# A31G324 register map
Vendor: ABOV Semiconductor Co., Ltd.; Series: A31G324; File version: 1.0
CPU: CM0PLUS r0p1, little endian, no MPU, no FPU, VTOR, 2 interrupt priority bits
Registers are 32-bit, read-write, reset 0x0 unless marked. A register's access mark holds for its fields unless they carry their own. Offsets are from the block's base; [hi:lo] are bit positions.

## DAC — 12-BIT D/A CONVERTER
Base 0x40003500
0x00 DR — D/A Converter Data Register
  [15:0] DACDR — D/A Converter Data (16-bit) The DACDR[15:0] is a binary format.
0x04 BR ro — D/A Converter Buffer Register
  [15:0] DACBR — D/A Converter Buffer Data (16-bit) The DACBR[15:0] is a binary format.
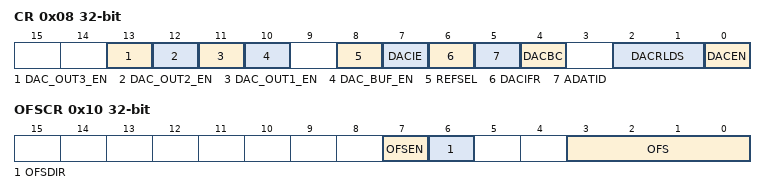
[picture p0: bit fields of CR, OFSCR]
0x08 CR — D/A Converter Control Register
  [13] DAC_OUT3_EN — DAC_OUT3 output enable 0:Disable, 1: Enable
  [12] DAC_OUT2_EN — DAC_OUT2 output enable 0:Disable, 1: Enable
  [11] DAC_OUT1_EN — DAC_OUT1 output enable 0:Disable, 1: Enable
  [10] DAC_BUF_EN — DAC Reference Selection 0:Disable, 1: Enable
  [8] REFSEL — DAC Reference Selection 0:AVDD, 1: DAVREF Pin
  [7] DACIE — Enable or Disable D/AC Interrupt
  [6] DACIFR — When D/AC Interrupt occurs, this bit becomes '1'. The flag is cleared only by writing a '0' to the bit. So, the flag should be cleared by software. This interrupt is for a result that the DACDRH register automatically increments to "800xH" or decrements to "000xH". Write '1' has no effect.
  [5] ADATID — Automatically D/A Converter Data Increment/Decrement
  [4] DACBC — D/A Converter Buffer Clear
  [2:1] DACRLDS — D/A Converter Reload Selection. These bits select a reload signal to load data from D/AC data register to buffer.
  [0] DACEN — D/A Converter Enable Bit
0x0C PGSR reset 0x5 — Programmable Gain Control Register
  [3:0] DACPGSR — Programmable Gain Selection
0x10 OFSCR — D/A Converter Offset Control Register
  [7] OFSEN — D/AC Offset Control Enable Bit
  [6] OFSDIR — D/AC Offset Direction Selection Bit
  [3:0] OFS — D/AC Offset Value

## COMP — COMPARATOR
Base 0x40003420
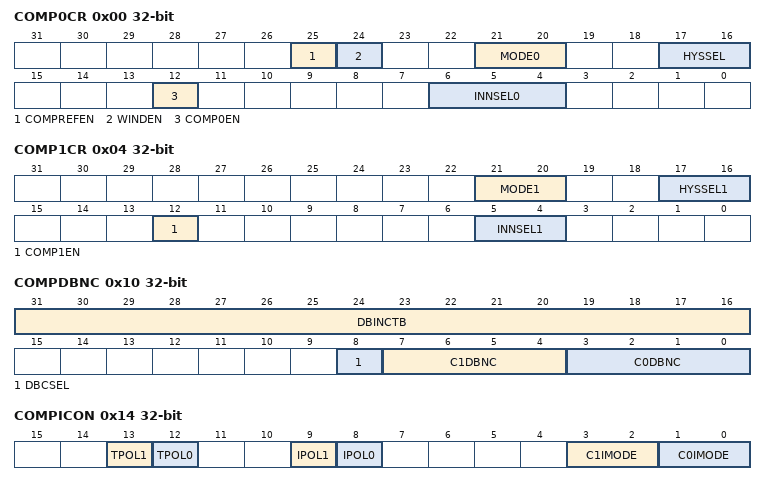
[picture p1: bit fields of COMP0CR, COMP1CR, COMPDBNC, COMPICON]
0x00 COMP0CR — Comparator 0 Control Register
  [25] COMPREFEN — Comparator internal reference voltage enable 0: Disable internal reference voltage 1: Enable internal reference voltage
  [24] WINDEN — Window mode Enable 0: Disable Window mode 1: Enable Window mode In Window mode, the input of Comparator 1 is connected to the input of comparator 0 (PA [01]), and the comparator 1 and PA [03] are disconnected.
  [21:20] MODE0 — Comparator 0 mode Selection 0: UL power 1: Low power 2: Medium power 3: High speed
  [17:16] HYSSEL — Comparator 0 Hysteresis mode selection 0: Off 1: Low 2: Medium 3: High
  [12] COMP0EN — Comparator 0 Enable 0: Disable Comparator 1: Enable Comparator
  [6:4] INNSEL0 — Comparator 0 Reference(input -) Selection
0x04 COMP1CR — Comparator 1 Control Register
  [21:20] MODE1 — Comparator 1 mode Selection 0: UL power 1: Low power 2: Medium power 3: High speed
  [17:16] HYSSEL1 — Comparator 1 Hysteresis mode selection 0: Off 1: Low 2: Medium 3: High
  [12] COMP1EN — Comparator 1 Enable 0: Disable Comparator 1: Enable Comparator
  [5:4] INNSEL1 — Comparator 0 Reference(input -) Selection
0x10 COMPDBNC — Comparator Debounce Register
  [31:16] DBINCTB — Debounce time base counter System clock/(DBNCTB *2) becomes shift clock of debounce logic When DBNCTB is 0, system clock would be debounce clock.
  [8] DBCSEL — Debounce clock selection 0:System clock 1:LSI500kHz
  [7:4] C1DBNC — Debounce shift Selection When it is 0x0, debounce function is disable Shift number of debounce logic is (C1DBNC + 1) when C1DBNC is more than 1
  [3:0] C0DBNC — Debounce shift Selection When it is 0x0, debounce function is disable Shift number of debounce logic is (C1DBNC + 1) when C1DBNC is more than 1
0x14 COMPICON — Comparator Interrupt Control Register
  [13] TPOL1 — Comparator Trigger output polarity(to trigger other IP) 0: output normal (comparator out high activates trigger) 1: output inverted (XOR)
  [12] TPOL0 — Comparator Trigger output polarity(to trigger other IP) 0: output normal (comparator out high activates trigger) 1: output inverted (XOR)
  [9] IPOL1 — Comparator 1 interrupt polarity(level mode) 0: interrupt at comparator out high 1: interrupt at comparator out low
  [8] IPOL0 — Comparator 0 interrupt polarity(level mode) 0: interrupt at comparator out high 1: interrupt at comparator out low
  [3:2] C1IMODE — Comparator 1 Interrupt Flag bit. 00: level interrupt (by IPOL1) 01: rising edge interrupt 10: falling edge interrupt 11: both edge interrupt A/D Converter Prescaler Data bits.
  [1:0] C0IMODE — Comparator 0 Interrupt Flag bit. 00: level interrupt (by IPOL0) 01: rising edge interrupt 10: falling edge interrupt 11: both edge interrupt A/D Converter Prescaler Data bits.
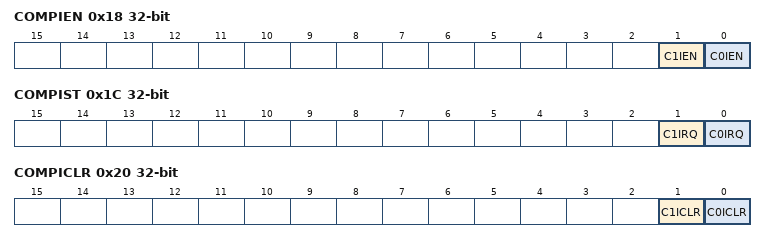
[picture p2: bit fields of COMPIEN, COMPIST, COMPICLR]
0x18 COMPIEN — Comparator Interrupt Enable Register
  [1] C1IEN — Comparator 1 Enable 0: Disable 1: Enable
  [0] C0IEN — Comparator 0 Enable 0: Disable 1: Enable
0x1C COMPIST ro — Comparator Interrupt Status Register
  [1] C1IRQ — Comparator 1 interrupt Status 0: No Comparator Interrupt 1: Comparator Interrupt asserted
  [0] C0IRQ — Comparator 0 interrupt Status 0: No Comparator Interrupt 1: Comparator Interrupt asserted
0x20 COMPICLR — Comparator Interrupt Clear Register
  [1] C1ICLR — Comparator 1 Interrupt Clear (write "1" to clear C1IRQ)
  [0] C0ICLR — Comparator 0 Interrupt Clear (write "1" to clear C0IRQ)
